# iostr730 register map
Registers are 16-bit, access not given, no defined reset value unless marked. A register's access mark holds for its fields unless they carry their own. Addresses are absolute; registers are grouped by the start of their names; [hi:lo] are bit positions; {n}, {i} and the like mark numbered series; 'fields as' and 'values as' point back to an identical list.

## CAN2
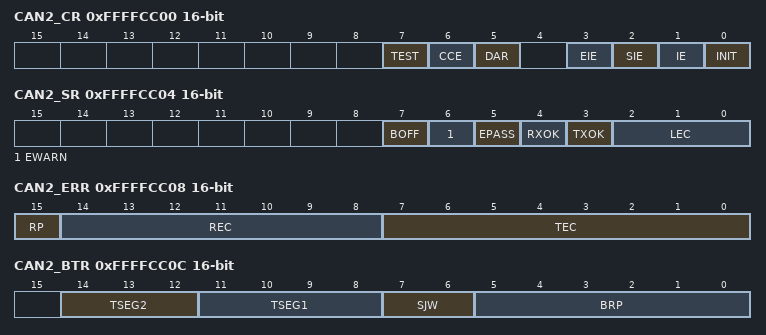
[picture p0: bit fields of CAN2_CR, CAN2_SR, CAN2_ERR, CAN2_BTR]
0xFFFFCC00 CAN2_CR
  [7] TEST, [6] CCE, [5] DAR, [3] EIE, [2] SIE, [1] IE, [0] INIT
0xFFFFCC04 CAN2_SR
  [7] BOFF, [6] EWARN, [5] EPASS, [4] RXOK, [3] TXOK, [2:0] LEC
0xFFFFCC08 CAN2_ERR
  [15] RP, [14:8] REC, [7:0] TEC
0xFFFFCC0C CAN2_BTR
  [14:12] TSEG2, [11:8] TSEG1, [7:6] SJW, [5:0] BRP
0xFFFFCC10 CAN2_IDR
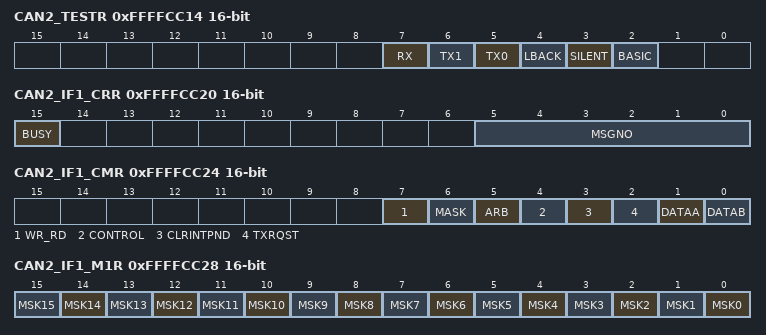
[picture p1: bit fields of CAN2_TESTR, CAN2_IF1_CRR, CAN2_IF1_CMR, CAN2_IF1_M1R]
0xFFFFCC14 CAN2_TESTR
  [7] RX, [6] TX1, [5] TX0, [4] LBACK, [3] SILENT, [2] BASIC
0xFFFFCC18 CAN2_BRPR
  [3:0] BRPE
0xFFFFCC20 CAN2_IF1_CRR
  [15] BUSY, [5:0] MSGNO
0xFFFFCC24 CAN2_IF1_CMR
  [7] WR_RD, [6] MASK, [5] ARB, [4] CONTROL, [3] CLRINTPND, [2] TXRQST, [1] DATAA, [0] DATAB
0xFFFFCC28 CAN2_IF1_M1R
  [n] MSK{n} (n=0..15)
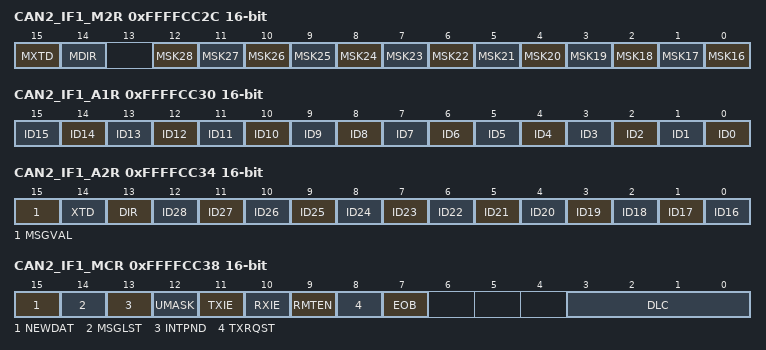
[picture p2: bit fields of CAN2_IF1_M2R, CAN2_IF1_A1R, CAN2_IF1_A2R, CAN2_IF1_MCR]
0xFFFFCC2C CAN2_IF1_M2R
  [15] MXTD, [14] MDIR, [n-16] MSK{n} (n=16..28)
0xFFFFCC30 CAN2_IF1_A1R
  [n] ID{n} (n=0..15)
0xFFFFCC34 CAN2_IF1_A2R
  [15] MSGVAL, [14] XTD, [13] DIR, [n-16] ID{n} (n=16..28)
0xFFFFCC38 CAN2_IF1_MCR
  [15] NEWDAT, [14] MSGLST, [13] INTPND, [12] UMASK, [11] TXIE, [10] RXIE, [9] RMTEN, [8] TXRQST, [7] EOB, [3:0] DLC
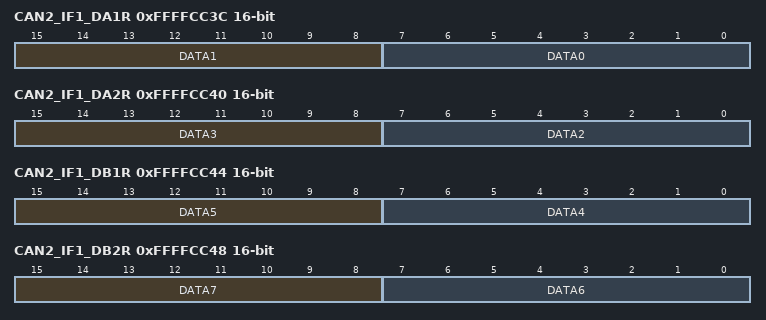
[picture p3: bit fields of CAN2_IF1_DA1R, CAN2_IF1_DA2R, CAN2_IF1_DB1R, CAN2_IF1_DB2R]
0xFFFFCC3C CAN2_IF1_DA1R
  [15:8] DATA1, [7:0] DATA0
0xFFFFCC40 CAN2_IF1_DA2R
  [15:8] DATA3, [7:0] DATA2
0xFFFFCC44 CAN2_IF1_DB1R
  [15:8] DATA5, [7:0] DATA4
0xFFFFCC48 CAN2_IF1_DB2R
  [15:8] DATA7, [7:0] DATA6
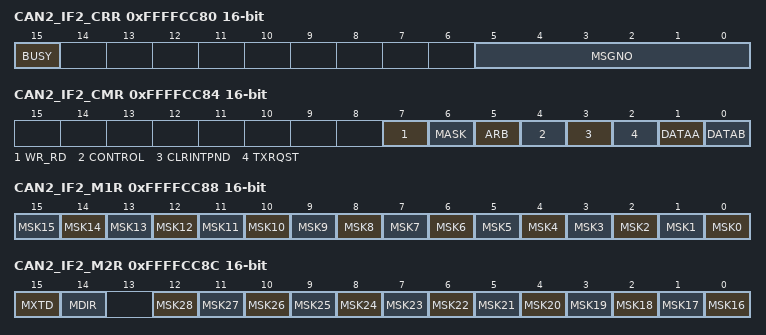
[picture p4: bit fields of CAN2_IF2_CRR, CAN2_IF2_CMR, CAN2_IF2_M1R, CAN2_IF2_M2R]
0xFFFFCC80 CAN2_IF2_CRR
  [15] BUSY, [5:0] MSGNO
0xFFFFCC84 CAN2_IF2_CMR
  fields as CAN2_IF1_CMR
0xFFFFCC88 CAN2_IF2_M1R
  [n] MSK{n} (n=0..15)
0xFFFFCC8C CAN2_IF2_M2R
  [15] MXTD, [14] MDIR, [n-16] MSK{n} (n=16..28)
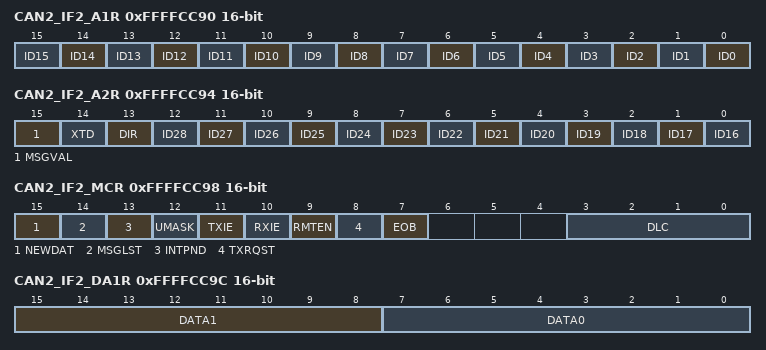
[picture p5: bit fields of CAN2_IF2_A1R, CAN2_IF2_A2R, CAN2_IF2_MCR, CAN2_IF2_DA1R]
0xFFFFCC90 CAN2_IF2_A1R
  [n] ID{n} (n=0..15)
0xFFFFCC94 CAN2_IF2_A2R
  [15] MSGVAL, [14] XTD, [13] DIR, [n-16] ID{n} (n=16..28)
0xFFFFCC98 CAN2_IF2_MCR
  fields as CAN2_IF1_MCR
0xFFFFCC9C CAN2_IF2_DA1R
  [15:8] DATA1, [7:0] DATA0
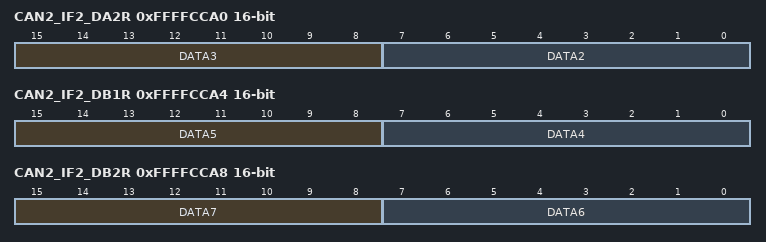
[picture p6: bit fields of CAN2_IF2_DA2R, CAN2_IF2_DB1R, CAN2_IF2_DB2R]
0xFFFFCCA0 CAN2_IF2_DA2R
  [15:8] DATA3, [7:0] DATA2
0xFFFFCCA4 CAN2_IF2_DB1R
  [15:8] DATA5, [7:0] DATA4
0xFFFFCCA8 CAN2_IF2_DB2R
  [15:8] DATA7, [7:0] DATA6
0xFFFFCD00 CAN2_TXR1R 32-bit
0xFFFFCD04 CAN2_TXR2R 32-bit
0xFFFFCD20 CAN2_ND1R 32-bit
0xFFFFCD24 CAN2_ND2R 32-bit
0xFFFFCD40 CAN2_IP1R 32-bit
0xFFFFCD44 CAN2_IP2R 32-bit
0xFFFFCD60 CAN2_MV1R 32-bit
0xFFFFCD64 CAN2_MV2R 32-bit

## PWM0
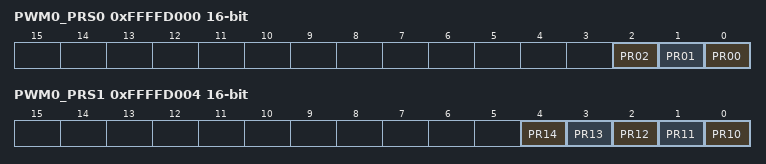
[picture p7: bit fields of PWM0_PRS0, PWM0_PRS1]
0xFFFFD000 PWM0_PRS0
  [2] PR02, [1] PR01, [0] PR00
0xFFFFD004 PWM0_PRS1
  [n-10] PR{n} (n=10..14)
0xFFFFD008 PWM0_PEN
  [0] PE
0xFFFFD00C PWM0_PLS
  [0] PL
0xFFFFD010 PWM0_CPI
  [0] CP
0xFFFFD014 PWM0_IM
  [0] IM
0xFFFFD01C PWM0_DUT
0xFFFFD020 PWM0_PER

## PWM1
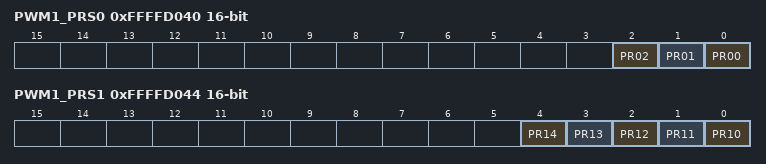
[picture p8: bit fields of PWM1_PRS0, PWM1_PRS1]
0xFFFFD040 PWM1_PRS0
  [2] PR02, [1] PR01, [0] PR00
0xFFFFD044 PWM1_PRS1
  [n-10] PR{n} (n=10..14)
0xFFFFD048 PWM1_PEN
  [0] PE
0xFFFFD04C PWM1_PLS
  [0] PL
0xFFFFD050 PWM1_CPI
  [0] CP
0xFFFFD054 PWM1_IM
  [0] IM
0xFFFFD05C PWM1_DUT
0xFFFFD060 PWM1_PER

## PWM2
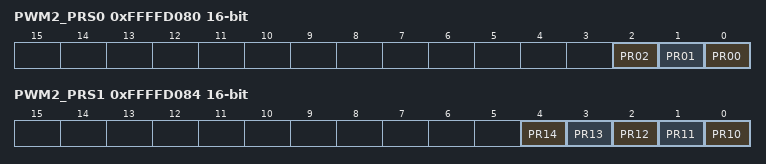
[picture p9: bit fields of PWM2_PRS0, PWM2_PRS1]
0xFFFFD080 PWM2_PRS0
  [2] PR02, [1] PR01, [0] PR00
0xFFFFD084 PWM2_PRS1
  [n-10] PR{n} (n=10..14)
0xFFFFD088 PWM2_PEN
  [0] PE
0xFFFFD08C PWM2_PLS
  [0] PL
0xFFFFD090 PWM2_CPI
  [0] CP
0xFFFFD094 PWM2_IM
  [0] IM
0xFFFFD09C PWM2_DUT
0xFFFFD0A0 PWM2_PER

## PWM3
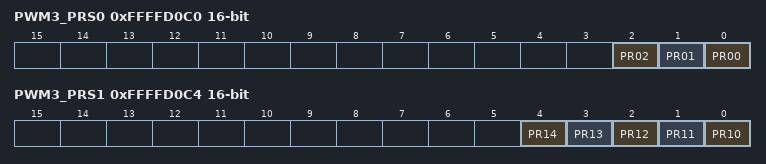
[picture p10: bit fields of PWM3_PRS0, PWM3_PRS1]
0xFFFFD0C0 PWM3_PRS0
  [2] PR02, [1] PR01, [0] PR00
0xFFFFD0C4 PWM3_PRS1
  [n-10] PR{n} (n=10..14)
0xFFFFD0C8 PWM3_PEN
  [0] PE
0xFFFFD0CC PWM3_PLS
  [0] PL
0xFFFFD0D0 PWM3_CPI
  [0] CP
0xFFFFD0D4 PWM3_IM
  [0] IM
0xFFFFD0DC PWM3_DUT
0xFFFFD0E0 PWM3_PER

## PWM4
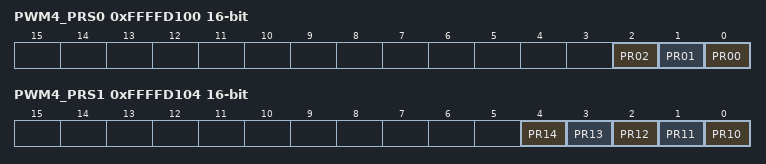
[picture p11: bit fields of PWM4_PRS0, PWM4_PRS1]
0xFFFFD100 PWM4_PRS0
  [2] PR02, [1] PR01, [0] PR00
0xFFFFD104 PWM4_PRS1
  [n-10] PR{n} (n=10..14)
0xFFFFD108 PWM4_PEN
  [0] PE
0xFFFFD10C PWM4_PLS
  [0] PL
0xFFFFD110 PWM4_CPI
  [0] CP
0xFFFFD114 PWM4_IM
  [0] IM
0xFFFFD11C PWM4_DUT
0xFFFFD120 PWM4_PER

## PWM5
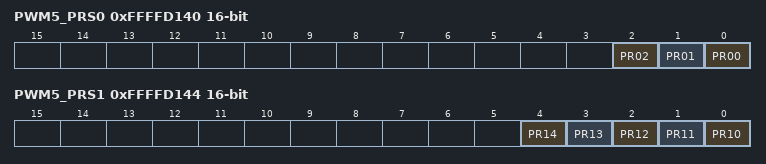
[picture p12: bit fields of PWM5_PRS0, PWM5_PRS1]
0xFFFFD140 PWM5_PRS0
  [2] PR02, [1] PR01, [0] PR00
0xFFFFD144 PWM5_PRS1
  [n-10] PR{n} (n=10..14)
0xFFFFD148 PWM5_PEN
  [0] PE
0xFFFFD14C PWM5_PLS
  [0] PL
0xFFFFD150 PWM5_CPI
  [0] CP
0xFFFFD154 PWM5_IM
  [0] IM
0xFFFFD15C PWM5_DUT
0xFFFFD160 PWM5_PER
